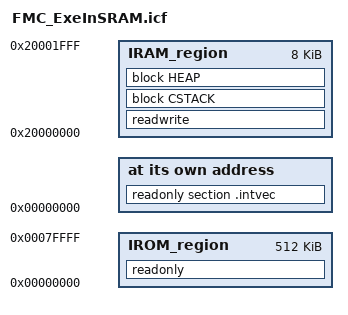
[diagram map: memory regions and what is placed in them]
/*###ICF### Section handled by ICF editor, don't touch! ****/
/*-Editor annotation file-*/
/* IcfEditorFile="$TOOLKIT_DIR$\config\ide\IcfEditor\cortex_v2_1.xml" */
/*-Specials-*/
define symbol __ICFEDIT_intvec_start__ = 0x00000000;
/*-Memory Regions-*/
define symbol __ICFEDIT_region_IROM1_start__ = 0x0;
define symbol __ICFEDIT_region_IROM1_end__   = 0x7FFFF;
define symbol __ICFEDIT_region_IRAM1_start__ = 0x20000000;
define symbol __ICFEDIT_region_IRAM1_end__   = 0x20001FFF;

/*-Sizes-*/
define symbol __ICFEDIT_size_cstack__        = 0x800;
define symbol __ICFEDIT_size_proc_s_stack__  = 0x0;
define symbol __ICFEDIT_size_main_ns_stack__ = 0x0;
define symbol __ICFEDIT_size_proc_ns_stack__ = 0x0;
define symbol __ICFEDIT_size_heap__          = 0x0;
/**** End of ICF editor section. ###ICF###*/

define memory mem with size = 4G;
define region IROM_region   =   mem:[from __ICFEDIT_region_IROM1_start__ to __ICFEDIT_region_IROM1_end__];
define region IRAM_region   =   mem:[from __ICFEDIT_region_IRAM1_start__ to __ICFEDIT_region_IRAM1_end__];

define block CSTACK        with alignment = 8, size = __ICFEDIT_size_cstack__        { };
define block HEAP          with alignment = 8, size = __ICFEDIT_size_heap__          { };

initialize by copy      { readwrite, readonly section fastcode};
initialize by copy      { readwrite, readonly object fmc.o};
initialize manually     { section fastcode };
//initialize by copy with packing = none { section __DLIB_PERTHREAD }; // Required in a multi-threaded application
do not initialize       { section .noinit };

place at address mem:__ICFEDIT_intvec_start__ { readonly section .intvec };

place in IROM_region             { readonly };
place in IRAM_region             { readwrite, block CSTACK, block HEAP };
